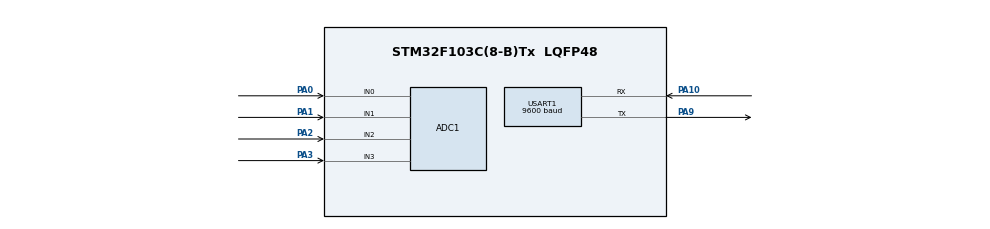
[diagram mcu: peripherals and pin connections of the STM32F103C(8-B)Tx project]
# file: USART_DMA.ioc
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ADC1.Channel-0\#ChannelRegularConversion=ADC_CHANNEL_0
ADC1.Channel-1\#ChannelRegularConversion=ADC_CHANNEL_1
ADC1.Channel-2\#ChannelRegularConversion=ADC_CHANNEL_2
ADC1.Channel-3\#ChannelRegularConversion=ADC_CHANNEL_3
ADC1.NbrOfConversion=4
ADC1.NbrOfConversionFlag=1
ADC1.Rank-0\#ChannelRegularConversion=1
ADC1.Rank-1\#ChannelRegularConversion=2
ADC1.Rank-2\#ChannelRegularConversion=3
ADC1.Rank-3\#ChannelRegularConversion=4
ADC1.SamplingTime-0\#ChannelRegularConversion=ADC_SAMPLETIME_55CYCLES_5
ADC1.SamplingTime-1\#ChannelRegularConversion=ADC_SAMPLETIME_55CYCLES_5
ADC1.SamplingTime-2\#ChannelRegularConversion=ADC_SAMPLETIME_55CYCLES_5
ADC1.SamplingTime-3\#ChannelRegularConversion=ADC_SAMPLETIME_55CYCLES_5
ADC1.master=1
Dma.ADC1.3.Direction=DMA_PERIPH_TO_MEMORY
Dma.ADC1.3.Instance=DMA1_Channel1
Dma.ADC1.3.MemDataAlignment=DMA_MDATAALIGN_HALFWORD
Dma.ADC1.3.MemInc=DMA_MINC_ENABLE
Dma.ADC1.3.Mode=DMA_CIRCULAR
Dma.ADC1.3.PeriphDataAlignment=DMA_PDATAALIGN_HALFWORD
Dma.ADC1.3.PeriphInc=DMA_PINC_DISABLE
Dma.ADC1.3.Priority=DMA_PRIORITY_MEDIUM
Dma.MEMTOMEM.2.Direction=DMA_MEMORY_TO_MEMORY
Dma.MEMTOMEM.2.Instance=DMA1_Channel2
Dma.MEMTOMEM.2.MemDataAlignment=DMA_MDATAALIGN_BYTE
Dma.MEMTOMEM.2.MemInc=DMA_MINC_ENABLE
Dma.MEMTOMEM.2.Mode=DMA_NORMAL
Dma.MEMTOMEM.2.PeriphDataAlignment=DMA_PDATAALIGN_BYTE
Dma.MEMTOMEM.2.PeriphInc=DMA_PINC_ENABLE
Dma.MEMTOMEM.2.Priority=DMA_PRIORITY_LOW
Dma.Request0=USART1_RX
Dma.Request1=USART1_TX
Dma.Request2=MEMTOMEM
Dma.Request3=ADC1
Dma.USART1_RX.0.Direction=DMA_PERIPH_TO_MEMORY
Dma.USART1_RX.0.Instance=DMA1_Channel5
Dma.USART1_RX.0.MemDataAlignment=DMA_MDATAALIGN_BYTE
Dma.USART1_RX.0.MemInc=DMA_MINC_ENABLE
Dma.USART1_RX.0.Mode=DMA_NORMAL
Dma.USART1_RX.0.PeriphDataAlignment=DMA_PDATAALIGN_BYTE
Dma.USART1_RX.0.PeriphInc=DMA_PINC_DISABLE
Dma.USART1_RX.0.Priority=DMA_PRIORITY_MEDIUM
Dma.USART1_TX.1.Direction=DMA_MEMORY_TO_PERIPH
Dma.USART1_TX.1.Instance=DMA1_Channel4
Dma.USART1_TX.1.MemDataAlignment=DMA_MDATAALIGN_BYTE
Dma.USART1_TX.1.MemInc=DMA_MINC_ENABLE
Dma.USART1_TX.1.Mode=DMA_NORMAL
Dma.USART1_TX.1.PeriphDataAlignment=DMA_PDATAALIGN_BYTE
Dma.USART1_TX.1.PeriphInc=DMA_PINC_DISABLE
Dma.USART1_TX.1.Priority=DMA_PRIORITY_MEDIUM
Mcu.Family=STM32F1
Mcu.Name=STM32F103C(8-B)Tx
Mcu.Package=LQFP48
NVIC.DMA1_Channel1_IRQn=true\:0\:0\:false\:false\:true\:false\:true\:true
NVIC.DMA1_Channel4_IRQn=true\:0\:0\:false\:false\:true\:false\:true\:true
NVIC.DMA1_Channel5_IRQn=true\:0\:0\:false\:false\:true\:false\:true\:true
NVIC.PriorityGroup=NVIC_PRIORITYGROUP_4
NVIC.RCC_IRQn=true\:0\:0\:false\:false\:true\:true\:false\:true
NVIC.USART1_IRQn=true\:0\:0\:false\:false\:true\:true\:true\:true
PA0-WKUP.Signal=ADCx_IN0
PA1.Signal=ADCx_IN1
PA10.GPIO_PuPd=GPIO_NOPULL
PA10.Mode=Asynchronous
PA10.Signal=USART1_RX
PA13.Mode=Serial_Wire
PA13.Signal=SYS_JTMS-SWDIO
PA14.Mode=Serial_Wire
PA14.Signal=SYS_JTCK-SWCLK
PA2.Signal=ADCx_IN2
PA3.Signal=ADCx_IN3
PA9.GPIO_Speed=GPIO_SPEED_FREQ_HIGH
PA9.Mode=Asynchronous
PA9.Signal=USART1_TX
PD0-OSC_IN.Mode=HSE-External-Oscillator
PD0-OSC_IN.Signal=RCC_OSC_IN
PD1-OSC_OUT.Mode=HSE-External-Oscillator
PD1-OSC_OUT.Signal=RCC_OSC_OUT
ProjectManager.HeapSize=0x200
ProjectManager.StackSize=0x400
ProjectManager.TargetToolchain=MDK-ARM V5.32
RCC.APB1Freq_Value=8000000
RCC.APB2Freq_Value=8000000
SH.ADCx_IN0.0=ADC1_IN0,IN0
SH.ADCx_IN1.0=ADC1_IN1,IN1
SH.ADCx_IN2.0=ADC1_IN2,IN2
SH.ADCx_IN3.0=ADC1_IN3,IN3
USART1.BaudRate=9600
USART1.VirtualMode=VM_ASYNC
board=custom

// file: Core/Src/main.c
/* USER CODE BEGIN Header */
/**
  ******************************************************************************
  * @file           : main.c
  * @brief          : Main program body
  ******************************************************************************
  * @attention
  *
  * Copyright (c) 2023 STMicroelectronics.
  * All rights reserved.
  *
  * This software is licensed under terms that can be found in the LICENSE file
  * in the root directory of this software component.
  * If no LICENSE file comes with this software, it is provided AS-IS.
  *
  ******************************************************************************
  */
/* USER CODE END Header */
#include "main.h"
#include "adc.h"
#include "dma.h"
#include "usart.h"
#include "gpio.h"

/* USER CODE BEGIN Includes */
 //int a= 455;
 uint8_t RXbuf[4] ;
 uint32_t ADCDate[4];
 float voltageCH0;
 float voltageCH1;
 float voltageCH2;
 float voltageCH3;
/* USER CODE END Includes */

void SystemClock_Config(void);

int main(void)
{

  /* MCU Configuration--------------------------------------------------------*/

  /* Reset of all peripherals, Initializes the Flash interface and the Systick. */
  HAL_Init();

  /* Configure the system clock */
  SystemClock_Config();

  /* Initialize all configured peripherals */
  MX_GPIO_Init();
  MX_DMA_Init();
  MX_USART1_UART_Init();
  MX_ADC1_Init();

  /* Infinite loop */
  while (1)
  {
      // printf("666");
       HAL_ADC_Start_DMA(&hadc1,ADCDate,4);
       HAL_Delay(2000);
       voltageCH0 =ADCDate[0];
       voltageCH1 =ADCDate[1];
       voltageCH2 =ADCDate[2];
       voltageCH3 =ADCDate[3];
       printf("\nCH0=%.f\n\nCH1=%.f\n\nCH2=%.f\n\nCH3=%.f",voltageCH0,voltageCH1,voltageCH2,voltageCH3);

  }
}

void SystemClock_Config(void)
{
  RCC_OscInitTypeDef RCC_OscInitStruct = {0};
  RCC_ClkInitTypeDef RCC_ClkInitStruct = {0};
  RCC_PeriphCLKInitTypeDef PeriphClkInit = {0};

  /** Initializes the RCC Oscillators according to the specified parameters
  * in the RCC_OscInitTypeDef structure.
  */
  RCC_OscInitStruct.OscillatorType = RCC_OSCILLATORTYPE_HSI;
  RCC_OscInitStruct.HSIState = RCC_HSI_ON;
  RCC_OscInitStruct.HSICalibrationValue = RCC_HSICALIBRATION_DEFAULT;
  RCC_OscInitStruct.PLL.PLLState = RCC_PLL_NONE;
  if (HAL_RCC_OscConfig(&RCC_OscInitStruct) != HAL_OK)
  {
    Error_Handler();
  }

  /** Initializes the CPU, AHB and APB buses clocks
  */
  RCC_ClkInitStruct.ClockType = RCC_CLOCKTYPE_HCLK|RCC_CLOCKTYPE_SYSCLK
                              |RCC_CLOCKTYPE_PCLK1|RCC_CLOCKTYPE_PCLK2;
  RCC_ClkInitStruct.SYSCLKSource = RCC_SYSCLKSOURCE_HSI;
  RCC_ClkInitStruct.AHBCLKDivider = RCC_SYSCLK_DIV1;
  RCC_ClkInitStruct.APB1CLKDivider = RCC_HCLK_DIV1;
  RCC_ClkInitStruct.APB2CLKDivider = RCC_HCLK_DIV1;

  if (HAL_RCC_ClockConfig(&RCC_ClkInitStruct, FLASH_LATENCY_0) != HAL_OK)
  {
    Error_Handler();
  }
  PeriphClkInit.PeriphClockSelection = RCC_PERIPHCLK_ADC;
  PeriphClkInit.AdcClockSelection = RCC_ADCPCLK2_DIV2;
  if (HAL_RCCEx_PeriphCLKConfig(&PeriphClkInit) != HAL_OK)
  {
    Error_Handler();
  }
}

void Error_Handler(void)
{
  __disable_irq();
  while (1)
  {
  }
}
